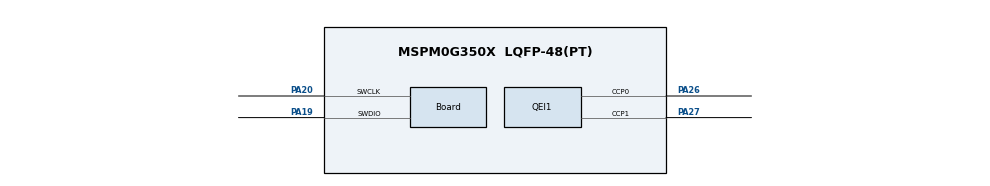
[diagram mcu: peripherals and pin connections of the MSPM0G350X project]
/**
 * @cliArgs --device "MSPM0G350X" --package "LQFP-48(PT)" --part "Default" --product "mspm0_sdk@2.01.00.03"
 * @versions {"tool":"1.20.0+3587"}
 */

/**
 * Import the modules used in this configuration.
 */
const GPIO          = scripting.addModule("/ti/driverlib/GPIO", {}, false);
const GPIO1         = GPIO.addInstance();
const QEI           = scripting.addModule("/ti/driverlib/QEI", {}, false);
const QEI1          = QEI.addInstance();
const SYSCTL        = scripting.addModule("/ti/driverlib/SYSCTL");
const ProjectConfig = scripting.addModule("/ti/project_config/ProjectConfig");

/**
 * Write custom configuration values to the imported modules.
 */
GPIO1.$name                              = "GPIO_OLED";
GPIO1.associatedPins.create(2);
GPIO1.associatedPins[0].$name            = "SCL";
GPIO1.associatedPins[0].initialValue     = "SET";
GPIO1.associatedPins[0].internalResistor = "PULL_UP";
GPIO1.associatedPins[0].assignedPort     = "PORTB";
GPIO1.associatedPins[0].assignedPin      = "6";
GPIO1.associatedPins[1].$name            = "SDA";
GPIO1.associatedPins[1].initialValue     = "SET";
GPIO1.associatedPins[1].internalResistor = "PULL_UP";
GPIO1.associatedPins[1].assignedPort     = "PORTB";
GPIO1.associatedPins[1].assignedPin      = "7";

const Board                       = scripting.addModule("/ti/driverlib/Board", {}, false);
Board.peripheral.$assign          = "DEBUGSS";
Board.peripheral.swclkPin.$assign = "PA20";
Board.peripheral.swdioPin.$assign = "PA19";

QEI1.$name                              = "QEI_ENCODER";
QEI1.interruptPriority                  = "0";
QEI1.peripheral.$assign                 = "TIMG8";
QEI1.peripheral.ccp0Pin.$assign         = "PA26";
QEI1.peripheral.ccp1Pin.$assign         = "PA27";
QEI1.ccp0PinConfig.$name                = "ti_driverlib_gpio_GPIOPinGeneric0";
QEI1.ccp0PinConfig.hideOutputInversion  = scripting.forceWrite(false);
QEI1.ccp0PinConfig.onlyInternalResistor = scripting.forceWrite(false);
QEI1.ccp0PinConfig.passedPeripheralType = scripting.forceWrite("Digital");
QEI1.ccp1PinConfig.$name                = "ti_driverlib_gpio_GPIOPinGeneric1";
QEI1.ccp1PinConfig.hideOutputInversion  = scripting.forceWrite(false);
QEI1.ccp1PinConfig.onlyInternalResistor = scripting.forceWrite(false);
QEI1.ccp1PinConfig.passedPeripheralType = scripting.forceWrite("Digital");

SYSCTL.forceDefaultClkConfig = true;
SYSCTL.peripheral.$assign    = "SYSCTL";

ProjectConfig.deviceSpin = "MSPM0G3507";

/**
 * Pinmux solution for unlocked pins/peripherals. This ensures that minor changes to the automatic solver in a future
 * version of the tool will not impact the pinmux you originally saw.  These lines can be completely deleted in order to
 * re-solve from scratch.
 */
GPIO1.associatedPins[0].pin.$suggestSolution = "PB6";
GPIO1.associatedPins[1].pin.$suggestSolution = "PB7";
